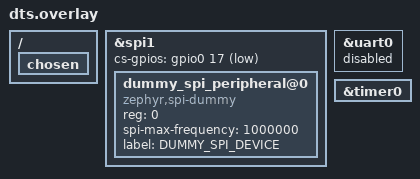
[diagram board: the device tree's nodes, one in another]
// app.overlay
/ {
    chosen {
        // If uart0 was the console, you might want to pick another one
        // or disable console output if uart0 is truly disabled for app use.
        // zephyr,console = &uart1; // Example if you have uart1
        // zephyr,shell-uart = &uart1; // Example
    };
};

&spi1 { // Assuming spi1 is the desired SPI controller
    status = "okay";
    cs-gpios = <&gpio0 17 GPIO_ACTIVE_LOW>; /* Example CS, adjust to your board */

    /* Example dummy SPI device on this bus */
    dummy_spi_peripheral@0 {
        compatible = "zephyr,spi-dummy"; // A generic compatible for example
        reg = <0>; // Chip select index 0 relative to spi1's cs-gpios
        spi-max-frequency = <1000000>;
        label = "DUMMY_SPI_DEVICE";
    };
};

&uart0 { // Assuming uart0 is the desired UART
    status = "disabled";
    // current-speed = <115200>; // Still good to have, but status="disabled" overrides
};

/*
 * For WiFi, the node label depends on your specific WiFi chip.
 * Common examples: &nrf_wifi (for nRF700x), &eswifi (for ST's EMW3080B),
 * &cyw43 (for Infineon CYW43xxx).
 * If you don't have a WiFi chip or don't specify this,
 * Kconfig options (CONFIG_WIFI=n) are the primary way to disable WiFi.
 */
// &nrf_wifi { // Example: Replace with your actual WiFi node label
//  status = "disabled";
// };
// &eswifi {
//  status = "disabled";
// };

&timer0 { // Assuming timer0 is the desired timer/counter
    status = "okay";
};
